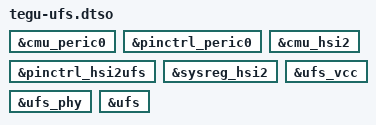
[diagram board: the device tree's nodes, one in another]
// SPDX-License-Identifier: MIT
/dts-v1/;
/plugin/;

/* Enable guarded UFS access to the Arch root on userdata. */
&cmu_peric0 { status = "okay"; };
&pinctrl_peric0 { status = "okay"; };
&cmu_hsi2 { status = "okay"; };
&pinctrl_hsi2ufs { status = "okay"; };
&sysreg_hsi2 { status = "okay"; };
&ufs_vcc { status = "okay"; };
&ufs_phy { status = "okay"; };
&ufs { status = "okay"; };
